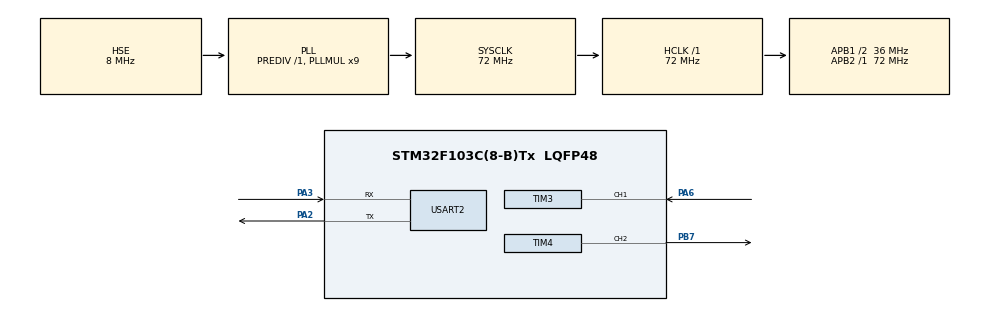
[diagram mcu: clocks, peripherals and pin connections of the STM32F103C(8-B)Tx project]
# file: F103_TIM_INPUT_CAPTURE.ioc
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Mcu.Family=STM32F1
Mcu.Name=STM32F103C(8-B)Tx
Mcu.Package=LQFP48
NVIC.PriorityGroup=NVIC_PRIORITYGROUP_4
NVIC.TIM3_IRQn=true\:0\:0\:false\:false\:true\:true\:true
PA13.Mode=Serial_Wire
PA13.Signal=SYS_JTMS-SWDIO
PA14.Mode=Serial_Wire
PA14.Signal=SYS_JTCK-SWCLK
PA2.Mode=Asynchronous
PA2.Signal=USART2_TX
PA3.Mode=Asynchronous
PA3.Signal=USART2_RX
PA6.Signal=S_TIM3_CH1
PB7.Signal=S_TIM4_CH2
PD0-OSC_IN.Mode=HSE-External-Oscillator
PD0-OSC_IN.Signal=RCC_OSC_IN
PD1-OSC_OUT.Mode=HSE-External-Oscillator
PD1-OSC_OUT.Signal=RCC_OSC_OUT
ProjectManager.HeapSize=0x200
ProjectManager.StackSize=0x400
ProjectManager.TargetToolchain=SW4STM32
RCC.AHBFreq_Value=72000000
RCC.APB1CLKDivider=RCC_HCLK_DIV2
RCC.APB1Freq_Value=36000000
RCC.APB1TimFreq_Value=72000000
RCC.APB2Freq_Value=72000000
RCC.APB2TimFreq_Value=72000000
RCC.HCLKFreq_Value=72000000
RCC.PLLMUL=RCC_PLL_MUL9
RCC.PLLSourceVirtual=RCC_PLLSOURCE_HSE
RCC.SYSCLKFreq_VALUE=72000000
RCC.SYSCLKSource=RCC_SYSCLKSOURCE_PLLCLK
RCC.USBFreq_Value=72000000
SH.S_TIM3_CH1.0=TIM3_CH1,Input_Capture1_from_TI1
SH.S_TIM4_CH2.0=TIM4_CH2,PWM Generation2 CH2
TIM3.Channel-Input_Capture1_from_TI1=TIM_CHANNEL_1
TIM3.Period=0xFFFF
TIM4.Channel-PWM\ Generation2\ CH2=TIM_CHANNEL_2
TIM4.OCFastMode_PWM-PWM\ Generation2\ CH2=TIM_OCFAST_ENABLE
TIM4.Period=1024-1
TIM4.Prescaler=18-1
TIM4.Pulse-PWM\ Generation2\ CH2=384
USART2.VirtualMode=VM_ASYNC
VP_TIM3_VS_ClockSourceINT.Mode=Internal
VP_TIM4_VS_ClockSourceINT.Mode=Internal
board=stm32f103-hal-tim-input-capture

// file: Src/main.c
/* USER CODE BEGIN Header */
/**
  ******************************************************************************
  * @file           : main.c
  * @brief          : Main program body
  ******************************************************************************
  * @attention
  *
  * <h2><center>&copy; Copyright (c) 2019 STMicroelectronics.
  * All rights reserved.</center></h2>
  *
  * This software component is licensed by ST under BSD 3-Clause license,
  * the "License"; You may not use this file except in compliance with the
  * License. You may obtain a copy of the License at:
  *                        opensource.org/licenses/BSD-3-Clause
  *
  ******************************************************************************
  */
/* USER CODE END Header */

#include "main.h"
#include "string.h"

TIM_HandleTypeDef htim3;
TIM_HandleTypeDef htim4;

UART_HandleTypeDef huart2;

/* USER CODE BEGIN PV */
char txBuffer[20] = "UART ILETIM BASLADI:\n";

uint32_t icValue1 = 0;
uint32_t icValue2 = 0;
uint32_t diffCapture = 0;
uint16_t captureIndex = 0;
double frequency = 0.0;
char strBuffer[32];
/* USER CODE END PV */

void SystemClock_Config(void);
static void MX_GPIO_Init(void);
static void MX_TIM4_Init(void);
static void MX_TIM3_Init(void);
static void MX_USART2_UART_Init(void);

int main(void)
{

  /* MCU Configuration--------------------------------------------------------*/

  /* Reset of all peripherals, Initializes the Flash interface and the Systick. */
  HAL_Init();

  /* Configure the system clock */
  SystemClock_Config();

  /* Initialize all configured peripherals */
  MX_GPIO_Init();
  MX_TIM4_Init();
  MX_TIM3_Init();
  MX_USART2_UART_Init();
  /* USER CODE BEGIN 2 */
	if (HAL_UART_Transmit(&huart2, (uint8_t*)txBuffer, sizeof(txBuffer),100) != HAL_OK)
	{
		Error_Handler();
	}

	HAL_TIM_PWM_Start(&htim4, TIM_CHANNEL_2);
	HAL_TIM_IC_Start_IT(&htim3, TIM_CHANNEL_1);
  /* USER CODE END 2 */

  /* Infinite loop */
  /* USER CODE BEGIN WHILE */
  while (1)
  {
		sprintf(strBuffer, "Frequency=%.2fHz\n", frequency);
		HAL_UART_Transmit(&huart2, (uint8_t *)strBuffer, strlen(strBuffer), 1);
		HAL_Delay(2000);
  }
  /* USER CODE END 3 */
}

void HAL_TIM_IC_CaptureCallback(TIM_HandleTypeDef *htim)
{
	if (htim->Channel == HAL_TIM_ACTIVE_CHANNEL_1)
	{
		if (captureIndex == 0)
		{
			/* Get the 1st input capture value */
			icValue1 = HAL_TIM_ReadCapturedValue(htim, TIM_CHANNEL_1);

			captureIndex = 1;
		}
		else if (captureIndex == 1)
		{
			/* Get the 2nd input capture value */
			icValue2 = HAL_TIM_ReadCapturedValue(htim, TIM_CHANNEL_1);

			/* Capture computation */
			if (icValue2 > icValue1)
			{
				diffCapture = icValue2 - icValue1;
			}
			else if (icValue2 < icValue1)
			{
				/* 0xFFFF is max TIM3 CCRx register value */
				diffCapture = ((0xFFFF-icValue1) + icValue2) + 1;
			}
			else
			{
				/* If capture values are equal, we have reached the limit of
				 * frequency measures */
				Error_Handler();
			}

			/* Frequency computation */
			/* TIM3CLK = 72 MHz */
			frequency = 72000000.0 / diffCapture;

			captureIndex = 0;
		}
	}
}
void SystemClock_Config(void)
{
  RCC_OscInitTypeDef RCC_OscInitStruct = {0};
  RCC_ClkInitTypeDef RCC_ClkInitStruct = {0};

  /** Initializes the CPU, AHB and APB busses clocks
  */
  RCC_OscInitStruct.OscillatorType = RCC_OSCILLATORTYPE_HSE;
  RCC_OscInitStruct.HSEState = RCC_HSE_ON;
  RCC_OscInitStruct.HSEPredivValue = RCC_HSE_PREDIV_DIV1;
  RCC_OscInitStruct.HSIState = RCC_HSI_ON;
  RCC_OscInitStruct.PLL.PLLState = RCC_PLL_ON;
  RCC_OscInitStruct.PLL.PLLSource = RCC_PLLSOURCE_HSE;
  RCC_OscInitStruct.PLL.PLLMUL = RCC_PLL_MUL9;
  if (HAL_RCC_OscConfig(&RCC_OscInitStruct) != HAL_OK)
  {
    Error_Handler();
  }
  /** Initializes the CPU, AHB and APB busses clocks
  */
  RCC_ClkInitStruct.ClockType = RCC_CLOCKTYPE_HCLK|RCC_CLOCKTYPE_SYSCLK
                              |RCC_CLOCKTYPE_PCLK1|RCC_CLOCKTYPE_PCLK2;
  RCC_ClkInitStruct.SYSCLKSource = RCC_SYSCLKSOURCE_PLLCLK;
  RCC_ClkInitStruct.AHBCLKDivider = RCC_SYSCLK_DIV1;
  RCC_ClkInitStruct.APB1CLKDivider = RCC_HCLK_DIV2;
  RCC_ClkInitStruct.APB2CLKDivider = RCC_HCLK_DIV1;

  if (HAL_RCC_ClockConfig(&RCC_ClkInitStruct, FLASH_LATENCY_2) != HAL_OK)
  {
    Error_Handler();
  }
}

static void MX_TIM3_Init(void)
{

  TIM_ClockConfigTypeDef sClockSourceConfig = {0};
  TIM_MasterConfigTypeDef sMasterConfig = {0};
  TIM_IC_InitTypeDef sConfigIC = {0};

  htim3.Instance = TIM3;
  htim3.Init.Prescaler = 0;
  htim3.Init.CounterMode = TIM_COUNTERMODE_UP;
  htim3.Init.Period = 0xFFFF;
  htim3.Init.ClockDivision = TIM_CLOCKDIVISION_DIV1;
  htim3.Init.AutoReloadPreload = TIM_AUTORELOAD_PRELOAD_DISABLE;
  if (HAL_TIM_Base_Init(&htim3) != HAL_OK)
  {
    Error_Handler();
  }
  sClockSourceConfig.ClockSource = TIM_CLOCKSOURCE_INTERNAL;
  if (HAL_TIM_ConfigClockSource(&htim3, &sClockSourceConfig) != HAL_OK)
  {
    Error_Handler();
  }
  if (HAL_TIM_IC_Init(&htim3) != HAL_OK)
  {
    Error_Handler();
  }
  sMasterConfig.MasterOutputTrigger = TIM_TRGO_RESET;
  sMasterConfig.MasterSlaveMode = TIM_MASTERSLAVEMODE_DISABLE;
  if (HAL_TIMEx_MasterConfigSynchronization(&htim3, &sMasterConfig) != HAL_OK)
  {
    Error_Handler();
  }
  sConfigIC.ICPolarity = TIM_INPUTCHANNELPOLARITY_RISING;
  sConfigIC.ICSelection = TIM_ICSELECTION_DIRECTTI;
  sConfigIC.ICPrescaler = TIM_ICPSC_DIV1;
  sConfigIC.ICFilter = 0;
  if (HAL_TIM_IC_ConfigChannel(&htim3, &sConfigIC, TIM_CHANNEL_1) != HAL_OK)
  {
    Error_Handler();
  }

}

static void MX_TIM4_Init(void)
{

  TIM_ClockConfigTypeDef sClockSourceConfig = {0};
  TIM_MasterConfigTypeDef sMasterConfig = {0};
  TIM_OC_InitTypeDef sConfigOC = {0};

  htim4.Instance = TIM4;
  htim4.Init.Prescaler = 0;
  htim4.Init.CounterMode = TIM_COUNTERMODE_UP;
  htim4.Init.Period = 1024-1;
  htim4.Init.ClockDivision = TIM_CLOCKDIVISION_DIV1;
  htim4.Init.AutoReloadPreload = TIM_AUTORELOAD_PRELOAD_DISABLE;
  if (HAL_TIM_Base_Init(&htim4) != HAL_OK)
  {
    Error_Handler();
  }
  sClockSourceConfig.ClockSource = TIM_CLOCKSOURCE_INTERNAL;
  if (HAL_TIM_ConfigClockSource(&htim4, &sClockSourceConfig) != HAL_OK)
  {
    Error_Handler();
  }
  if (HAL_TIM_PWM_Init(&htim4) != HAL_OK)
  {
    Error_Handler();
  }
  sMasterConfig.MasterOutputTrigger = TIM_TRGO_RESET;
  sMasterConfig.MasterSlaveMode = TIM_MASTERSLAVEMODE_DISABLE;
  if (HAL_TIMEx_MasterConfigSynchronization(&htim4, &sMasterConfig) != HAL_OK)
  {
    Error_Handler();
  }
  sConfigOC.OCMode = TIM_OCMODE_PWM1;
  sConfigOC.Pulse = 512;
  sConfigOC.OCPolarity = TIM_OCPOLARITY_HIGH;
  sConfigOC.OCFastMode = TIM_OCFAST_ENABLE;
  if (HAL_TIM_PWM_ConfigChannel(&htim4, &sConfigOC, TIM_CHANNEL_2) != HAL_OK)
  {
    Error_Handler();
  }
  HAL_TIM_MspPostInit(&htim4);

}

static void MX_USART2_UART_Init(void)
{

  huart2.Instance = USART2;
  huart2.Init.BaudRate = 115200;
  huart2.Init.WordLength = UART_WORDLENGTH_8B;
  huart2.Init.StopBits = UART_STOPBITS_1;
  huart2.Init.Parity = UART_PARITY_NONE;
  huart2.Init.Mode = UART_MODE_TX_RX;
  huart2.Init.HwFlowCtl = UART_HWCONTROL_NONE;
  huart2.Init.OverSampling = UART_OVERSAMPLING_16;
  if (HAL_UART_Init(&huart2) != HAL_OK)
  {
    Error_Handler();
  }

}

static void MX_GPIO_Init(void)
{
  GPIO_InitTypeDef GPIO_InitStruct = {0};

  /* GPIO Ports Clock Enable */
  __HAL_RCC_GPIOC_CLK_ENABLE();
  __HAL_RCC_GPIOD_CLK_ENABLE();
  __HAL_RCC_GPIOA_CLK_ENABLE();
  __HAL_RCC_GPIOB_CLK_ENABLE();

  /*Configure GPIO pins : PC13 PC14 PC15 */
  GPIO_InitStruct.Pin = GPIO_PIN_13|GPIO_PIN_14|GPIO_PIN_15;
  GPIO_InitStruct.Mode = GPIO_MODE_ANALOG;
  HAL_GPIO_Init(GPIOC, &GPIO_InitStruct);

  /*Configure GPIO pins : PA0 PA1 PA4 PA5
                           PA7 PA8 PA9 PA10
                           PA11 PA12 PA15 */
  GPIO_InitStruct.Pin = GPIO_PIN_0|GPIO_PIN_1|GPIO_PIN_4|GPIO_PIN_5
                          |GPIO_PIN_7|GPIO_PIN_8|GPIO_PIN_9|GPIO_PIN_10
                          |GPIO_PIN_11|GPIO_PIN_12|GPIO_PIN_15;
  GPIO_InitStruct.Mode = GPIO_MODE_ANALOG;
  HAL_GPIO_Init(GPIOA, &GPIO_InitStruct);

  /*Configure GPIO pins : PB0 PB1 PB2 PB10
                           PB11 PB12 PB13 PB14
                           PB15 PB3 PB4 PB5
                           PB6 PB8 PB9 */
  GPIO_InitStruct.Pin = GPIO_PIN_0|GPIO_PIN_1|GPIO_PIN_2|GPIO_PIN_10
                          |GPIO_PIN_11|GPIO_PIN_12|GPIO_PIN_13|GPIO_PIN_14
                          |GPIO_PIN_15|GPIO_PIN_3|GPIO_PIN_4|GPIO_PIN_5
                          |GPIO_PIN_6|GPIO_PIN_8|GPIO_PIN_9;
  GPIO_InitStruct.Mode = GPIO_MODE_ANALOG;
  HAL_GPIO_Init(GPIOB, &GPIO_InitStruct);

}

void Error_Handler(void)
{
}

/************************ (C) COPYRIGHT STMicroelectronics *****END OF FILE****/
